# STM32WB15CCU6 register map
File version: 1.0
Registers are 32-bit, access not given, reset 0x0 unless marked. A register's access mark holds for its fields unless they carry their own. Offsets are from the block's base; [hi:lo] are bit positions; {n}, {i} and the like mark numbered series; 'fields as' and 'values as' point back to an identical list.

## CRC
Base 0x40023000
0x00 DR
0x04 IDR
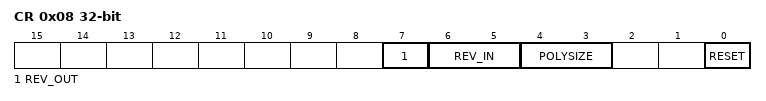
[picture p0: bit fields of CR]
0x08 CR
  [7] REV_OUT, [6:5] REV_IN, [4:3] POLYSIZE, [0] RESET
0x10 INIT
  [31:0] CRC_INIT
0x14 POL

## TSC
Base 0x40024000
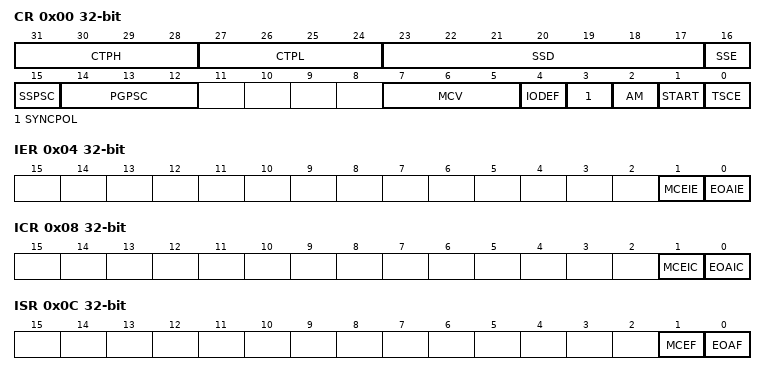
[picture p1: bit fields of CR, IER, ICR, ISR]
0x00 CR
  [31:28] CTPH, [27:24] CTPL, [23:17] SSD, [16] SSE, [15] SSPSC, [14:12] PGPSC, [7:5] MCV, [4] IODEF, [3] SYNCPOL, [2] AM, [1] START, [0] TSCE
0x04 IER
  [1] MCEIE, [0] EOAIE
0x08 ICR
  [1] MCEIC, [0] EOAIC
0x0C ISR
  [1] MCEF, [0] EOAF
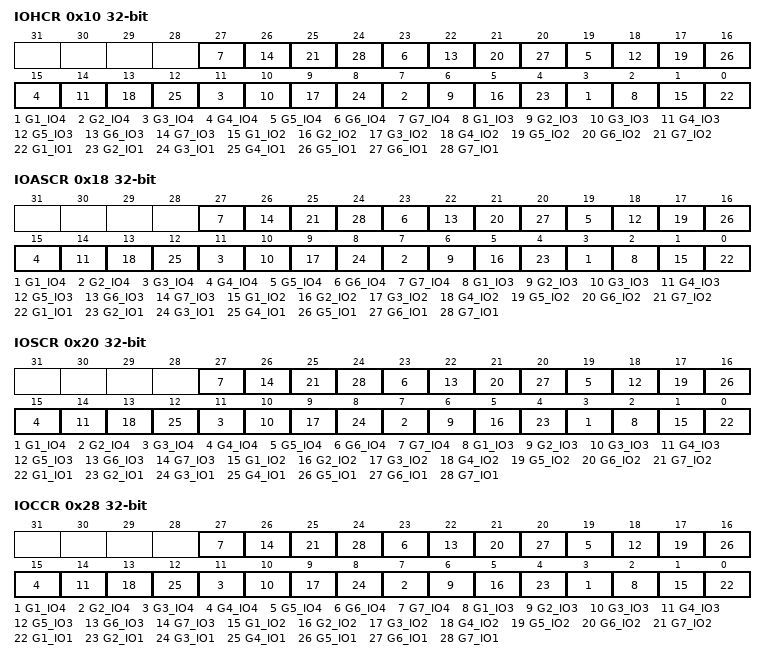
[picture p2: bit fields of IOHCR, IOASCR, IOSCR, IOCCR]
0x10 IOHCR
  [4n-1] G{n}_IO4 (n=1..7), [4n-2] G{n}_IO3 (n=1..7), [4n-3] G{n}_IO2 (n=1..7), [4n-4] G{n}_IO1 (n=1..7)
0x18 IOASCR
  fields as IOHCR
0x20 IOSCR
  fields as IOHCR
0x28 IOCCR
  fields as IOHCR
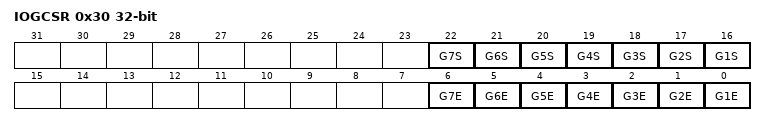
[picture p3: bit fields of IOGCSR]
0x30 IOGCSR
  [n+15] G{n}S (n=1..7), [n-1] G{n}E (n=1..7)
{0x30+4i} IOG{i}CR (i=1..7)
  [13:0] CNT

## GPIOA
Base 0x48000000
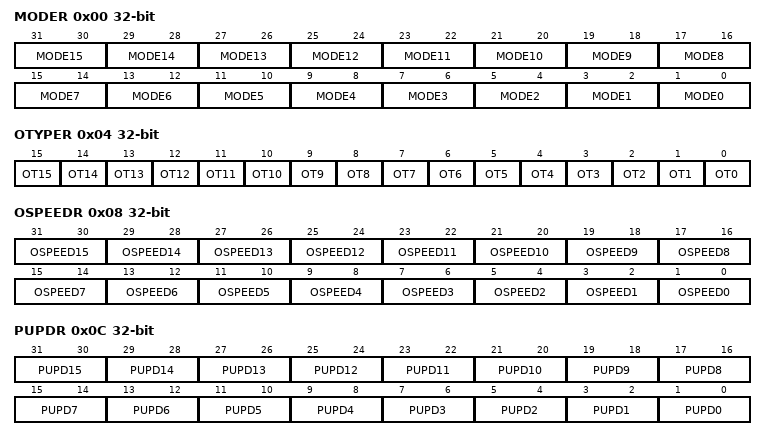
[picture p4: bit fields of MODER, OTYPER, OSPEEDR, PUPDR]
0x00 MODER
  [2n+1:2n] MODE{n} (n=0..15)
0x04 OTYPER
  [n] OT{n} (n=0..15)
0x08 OSPEEDR
  [2n+1:2n] OSPEED{n} (n=0..15)
0x0C PUPDR
  [2n+1:2n] PUPD{n} (n=0..15)
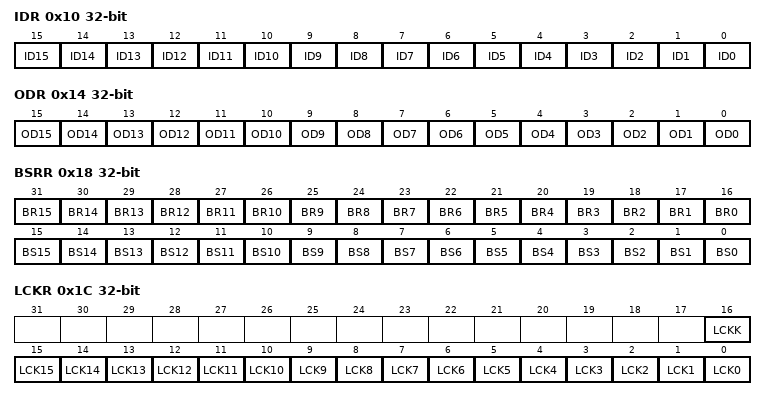
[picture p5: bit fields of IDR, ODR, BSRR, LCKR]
0x10 IDR
  [n] ID{n} (n=0..15)
0x14 ODR
  [n] OD{n} (n=0..15)
0x18 BSRR
  [n+16] BR{n} (n=0..15), [n] BS{n} (n=0..15)
0x1C LCKR
  [16] LCKK, [n] LCK{n} (n=0..15)
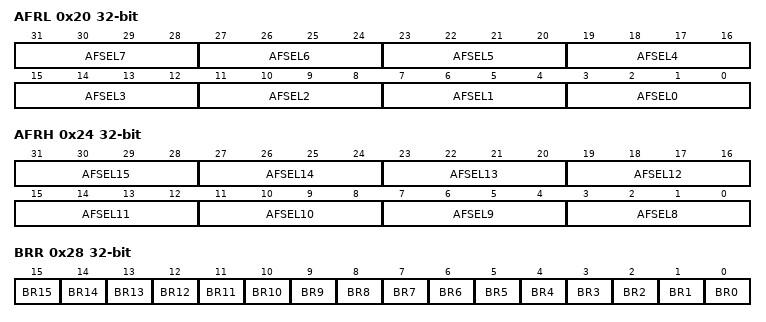
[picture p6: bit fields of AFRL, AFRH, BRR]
0x20 AFRL
  [4n+3:4n] AFSEL{n} (n=0..7)
0x24 AFRH
  [4n-29:4n-32] AFSEL{n} (n=8..15)
0x28 BRR
  [n] BR{n} (n=0..15)

## GPIOB
Base 0x48000400
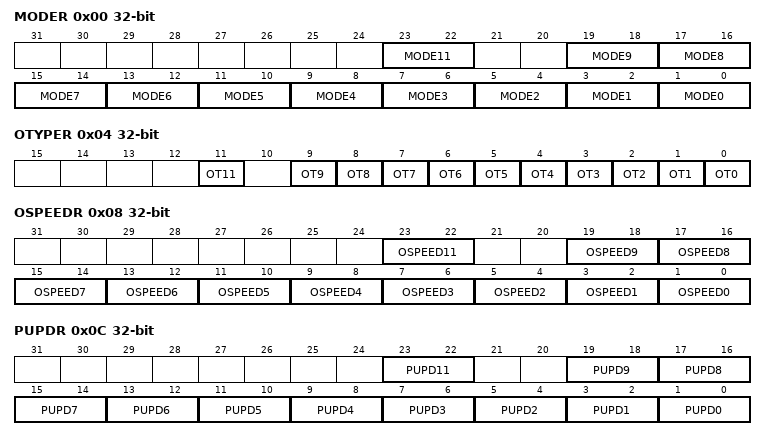
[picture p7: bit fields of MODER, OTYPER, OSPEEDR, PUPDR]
0x00 MODER
  [23:22] MODE11, [2n+1:2n] MODE{n} (n=0..9)
0x04 OTYPER
  [11] OT11, [n] OT{n} (n=0..9)
0x08 OSPEEDR
  [23:22] OSPEED11, [2n+1:2n] OSPEED{n} (n=0..9)
0x0C PUPDR
  [23:22] PUPD11, [2n+1:2n] PUPD{n} (n=0..9)
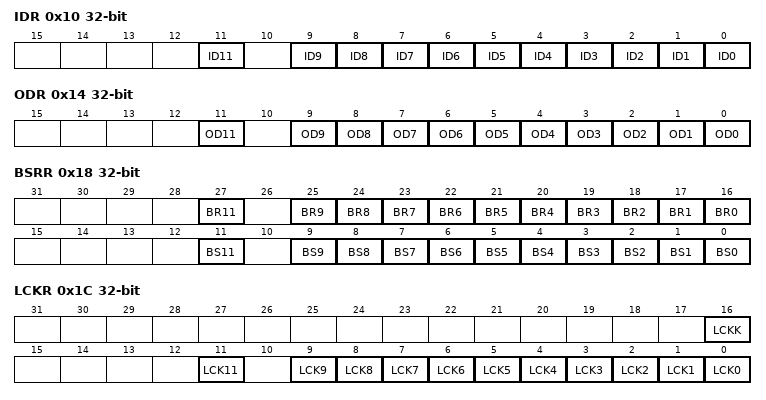
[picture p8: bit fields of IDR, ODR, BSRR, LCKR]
0x10 IDR
  [11] ID11, [n] ID{n} (n=0..9)
0x14 ODR
  [11] OD11, [n] OD{n} (n=0..9)
0x18 BSRR
  [27] BR11, [n+16] BR{n} (n=0..9), [11] BS11, [n] BS{n} (n=0..9)
0x1C LCKR
  [16] LCKK, [11] LCK11, [n] LCK{n} (n=0..9)
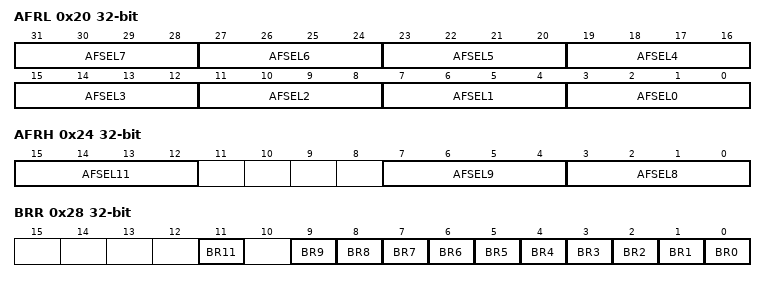
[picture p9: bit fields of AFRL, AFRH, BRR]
0x20 AFRL
  [4n+3:4n] AFSEL{n} (n=0..7)
0x24 AFRH
  [15:12] AFSEL11, [7:4] AFSEL9, [3:0] AFSEL8
0x28 BRR
  [11] BR11, [n] BR{n} (n=0..9)

## GPIOC
Base 0x48000800
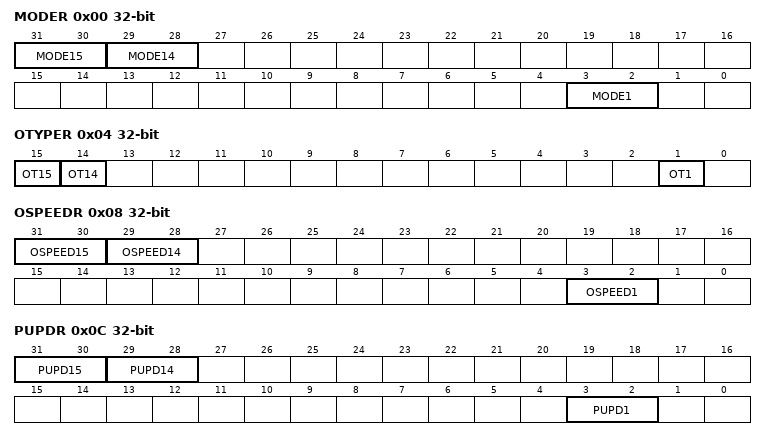
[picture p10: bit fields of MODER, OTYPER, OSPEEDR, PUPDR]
0x00 MODER
  [31:30] MODE15, [29:28] MODE14, [3:2] MODE1
0x04 OTYPER
  [15] OT15, [14] OT14, [1] OT1
0x08 OSPEEDR
  [31:30] OSPEED15, [29:28] OSPEED14, [3:2] OSPEED1
0x0C PUPDR
  [31:30] PUPD15, [29:28] PUPD14, [3:2] PUPD1
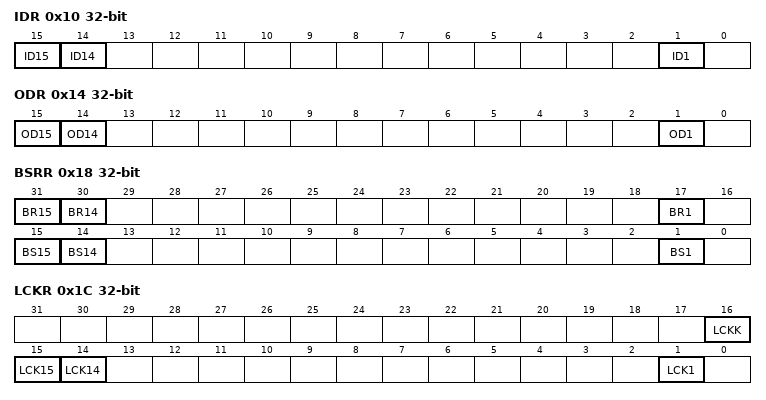
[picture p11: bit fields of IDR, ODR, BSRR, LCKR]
0x10 IDR
  [15] ID15, [14] ID14, [1] ID1
0x14 ODR
  [15] OD15, [14] OD14, [1] OD1
0x18 BSRR
  [31] BR15, [30] BR14, [17] BR1, [15] BS15, [14] BS14, [1] BS1
0x1C LCKR
  [16] LCKK, [15] LCK15, [14] LCK14, [1] LCK1
0x20 AFRL
  [7:4] AFSEL1
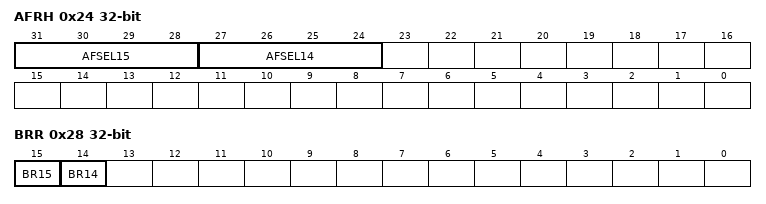
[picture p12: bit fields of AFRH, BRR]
0x24 AFRH
  [31:28] AFSEL15, [27:24] AFSEL14
0x28 BRR
  [15] BR15, [14] BR14

## GPIOE
Base 0x48001000
0x00 MODER
  [9:8] MODE4
0x04 OTYPER
  [4] OT4
0x08 OSPEEDR
  [9:8] OSPEED4
0x0C PUPDR
  [9:8] PUPD4
0x10 IDR
  [4] ID4
0x14 ODR
  [4] OD4
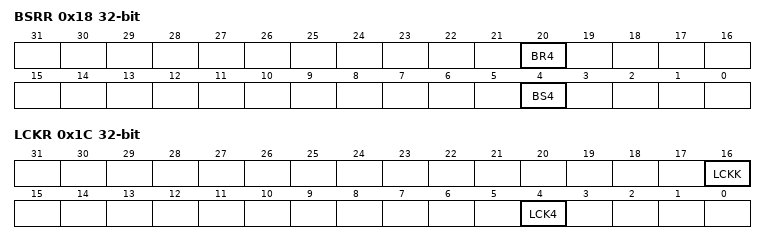
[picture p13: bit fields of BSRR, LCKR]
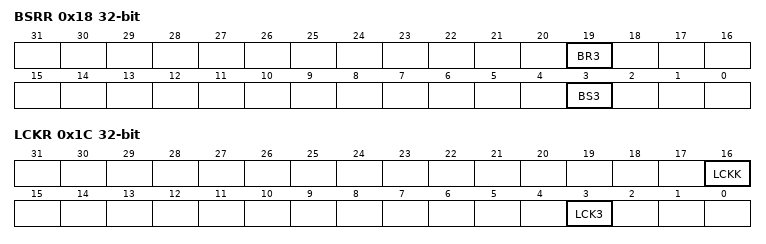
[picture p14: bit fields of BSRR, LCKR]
0x18 BSRR
  [20] BR4, [4] BS4
0x1C LCKR
  [16] LCKK, [4] LCK4
0x20 AFRL
  [19:16] AFSEL4
0x28 BRR
  [4] BR4

## GPIOH
Base 0x48001C00
0x00 MODER
  [7:6] MODE3
0x04 OTYPER
  [3] OT3
0x08 OSPEEDR
  [7:6] OSPEED3
0x0C PUPDR
  [7:6] PUPD3
0x10 IDR
  [3] ID3
0x14 ODR
  [3] OD3
0x18 BSRR
  [19] BR3, [3] BS3
0x1C LCKR
  [16] LCKK, [3] LCK3
0x20 AFRL
  [15:12] AFSEL3
0x28 BRR
  [3] BR3

## PWR
Base 0x58000400
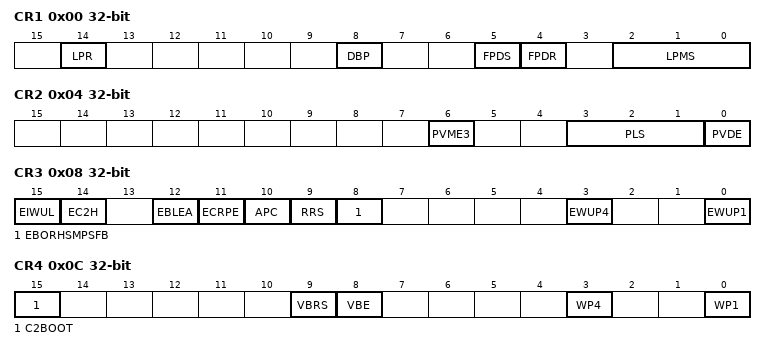
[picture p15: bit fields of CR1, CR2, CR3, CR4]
0x00 CR1
  [14] LPR, [8] DBP, [5] FPDS, [4] FPDR, [2:0] LPMS
0x04 CR2
  [6] PVME3, [3:1] PLS, [0] PVDE
0x08 CR3
  [15] EIWUL, [14] EC2H, [12] EBLEA, [11] ECRPE, [10] APC, [9] RRS, [8] EBORHSMPSFB, [3] EWUP4, [0] EWUP1
0x0C CR4
  [15] C2BOOT, [9] VBRS, [8] VBE, [3] WP4, [0] WP1
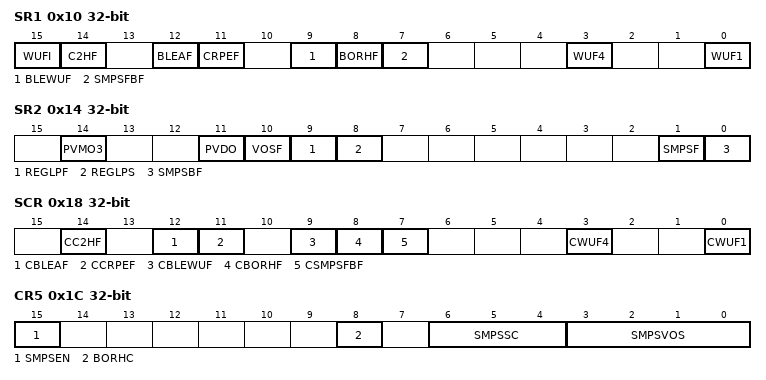
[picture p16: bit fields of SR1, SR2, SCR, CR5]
0x10 SR1
  [15] WUFI, [14] C2HF, [12] BLEAF, [11] CRPEF, [9] BLEWUF, [8] BORHF, [7] SMPSFBF, [3] WUF4, [0] WUF1
0x14 SR2
  [14] PVMO3, [11] PVDO, [10] VOSF, [9] REGLPF, [8] REGLPS, [1] SMPSF, [0] SMPSBF
0x18 SCR
  [14] CC2HF, [12] CBLEAF, [11] CCRPEF, [9] CBLEWUF, [8] CBORHF, [7] CSMPSFBF, [3] CWUF4, [0] CWUF1
0x1C CR5
  [15] SMPSEN, [8] BORHC, [6:4] SMPSSC, [3:0] SMPSVOS
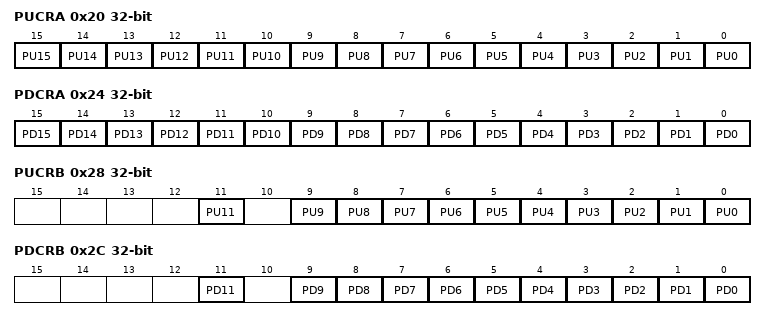
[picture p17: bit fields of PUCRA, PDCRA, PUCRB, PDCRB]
0x20 PUCRA
  [n] PU{n} (n=0..15)
0x24 PDCRA
  [n] PD{n} (n=0..15)
0x28 PUCRB
  [11] PU11, [n] PU{n} (n=0..9)
0x2C PDCRB
  [11] PD11, [n] PD{n} (n=0..9)
0x30 PUCRC
  [15] PU15, [14] PU14
0x34 PDCRC
  [15] PD15, [14] PD14
0x40 PUCRE
  [4] PU4
0x44 PDCRE
  [4] PD4
0x58 PUCRH
  [3] PU3
0x5C PDCRH
  [3] PD3
0x80 C2CR1
  [14] BLEEWKUP, [5] FPDS, [4] FPDR, [2:0] LPMS
0x84 C2CR3
  [15] EIWUL, [12] APC, [9] EBLEWUP, [3] EWUP4, [0] EWUP1
0x88 EXTSCR
  [15] C2DS, [14] C1DS, [13] CRPF, [11] C2STOPF, [10] C2SBF, [9] C1STOPF, [8] C1SBF, [2] CCRPF, [1] C2CSSF, [0] C1CSSF

## EXTI
Base 0x58000800
0x00 RTSR1
  [20:0] RT
0x04 FTSR1
  [20:0] FT
0x08 SWIER1
  [20:0] SWI
0x0C PR1
  [20:0] PIF
0x20 RTSR2
  [9:8] RT, [1] RT33
0x24 FTSR2
  [9:8] FT, [1] FT33
0x28 SWIER2
  [9:8] SWI, [1] SWI33
0x2C PR2
  [9:8] PIF, [1] PIF33
0x80 IMR1
  [22] IM22, [30:0] IM
0x84 EMR1
  [20:0] EM
0x90 IMR2
  [16:1] IM
0x94 EMR2
  [8] EM:40
0xC0 C2IMR1
  [22] IM22, [30:0] IM
0xC4 C2EMR1
  [20:0] EM
0xD0 C2IMR2
  [16] IM48, [13:4] IM, [1] IM33
0xD4 C2EMR2
  [9] EM41

## IPCC
Base 0x58000C00
0x00 C1CR
  [16] TXFIE, [0] RXOIE
0x04 C1MR
  [n+15] CH{n}FM (n=1..6), [n-1] CH{n}OM (n=1..6)
0x08 C1SCR
  [n+15] CH{n}S (n=1..6), [n-1] CH{n}C (n=1..6)
0x0C C1TOC2SR
  [n-1] CH{n}F (n=1..6)
0x10 C2CR
  [16] TXFIE, [0] RXOIE
0x14 C2MR
  [n+15] CH{n}FM (n=1..6), [n-1] CH{n}OM (n=1..6)
0x18 C2SCR
  [n+15] CH{n}S (n=1..6), [n-1] CH{n}C (n=1..6)
0x1C C2TOC1SR
  [n-1] CH{n}F (n=1..6)

## TRNG
Base 0x58001000
0x00 CR
  [5] CED, [3] IE, [2] RNGEN
0x04 SR
  [6] SEIS, [5] CEIS, [2] SECS, [1] CECS, [0] DRDY
0x08 DR
  [31:0] RNDATA

## HSEM
Base 0x58001400
{0x0+4i} R{i} (i=0..31)
  [31] LOCK, [11:8] COREID, [7:0] PROCID
{0x80+4i} RLR{i} (i=0..31)
  [31] LOCK, [11:8] COREID, [7:0] PROCID
0x100 C1IER
  [31:0] ISE
0x104 C1ICR
  [31:0] ISC
0x108 C1ISR
  [31:0] ISF
0x10C C1MISR
  [31:0] MISF
0x110 C2IER
  [31:0] ISE
0x114 C2ICR
  [31:0] ISC
0x118 C2ISR
  [31:0] ISF
0x11C C2MISR
  [31:0] MISF
0x140 CR
  [31:16] KEY, [11:8] COREID
0x144 KEYR
  [31:16] KEY

## AES2
Base 0x58001800
0x00 CR
  [23:20] NPBLB, [18] KEYSIZE, [14:13] GCMPH, [12] DMAOUTEN, [11] DMAINEN, [10] ERRIE, [9] CCFIE, [8] ERRC, [7] CCFC, [16:5] CHMOD, [4:3] MODE, [2:1] DATATYPE, [0] EN
0x04 SR
  [3] BUSY, [2] WRERR, [1] RDERR, [0] CCF
0x08 DINR
  [31:0] DIN
0x0C DOUTR
  [31:0] DOUT
{0x10+4i} KEYR{i} (i=0..3)
  [31:0] KEY
{0x20+4i} IVR{i} (i=0..3)
  [31:0] IVI
{0x20+4i} KEYR{i} (i=4..7)
  [31:0] KEY
{0x40+4i} SUSP{i}R (i=0..7)
  [31:0] SUSP

## PKA
Base 0x58002000
Same registers: PKARAM 0x58002400
0x00 CR
  [20] ADDRERRIE, [19] RAMERRIE, [17] PROCENDIE, [13:8] MODE, [1] START, [0] EN
0x04 SR
  [20] ADDRERRF, [19] RAMERRF, [17] PROCENDF, [16] BUSY
0x08 CLRFR
  [20] ADDRERRFC, [19] RAMERRFC, [17] PROCENDFC
